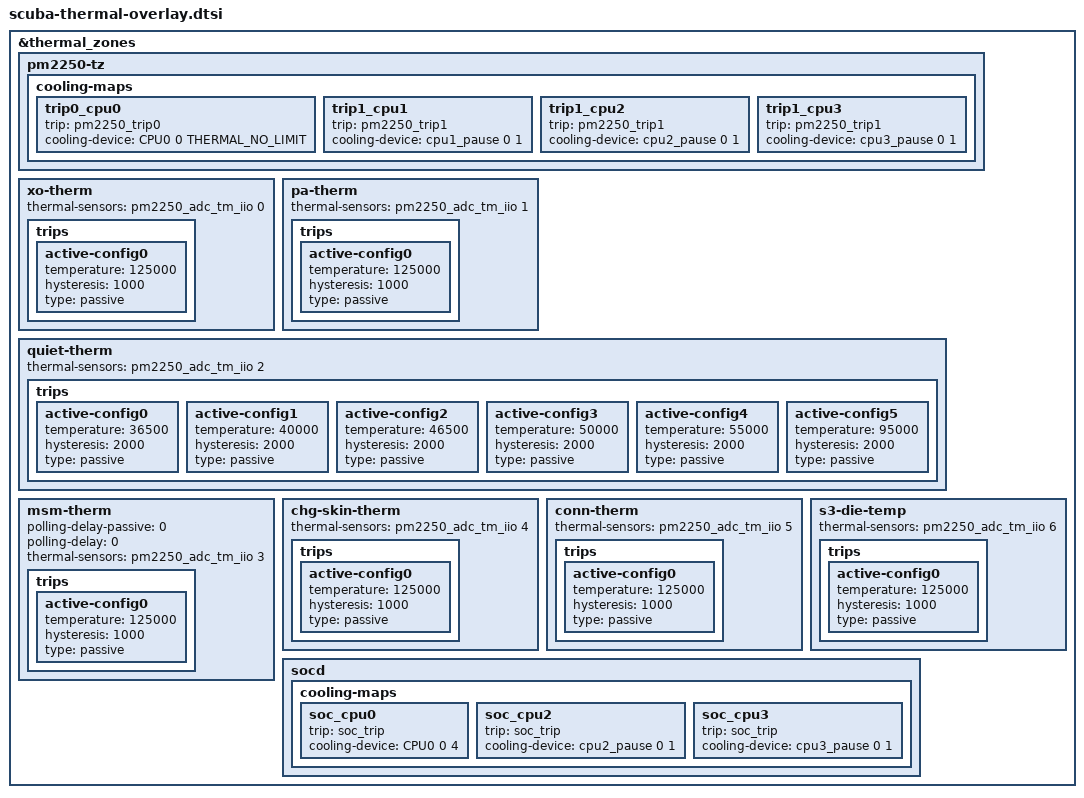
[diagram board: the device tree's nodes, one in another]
// SPDX-License-Identifier: BSD-3-Clause
/*
 * Copyright (c) Qualcomm Technologies, Inc. and/or its subsidiaries.
 */

#include <dt-bindings/thermal/thermal.h>

&thermal_zones {
	pm2250-tz {
		cooling-maps {
			trip0_cpu0 {
				trip = <&pm2250_trip0>;
				cooling-device =
					<&CPU0 0 THERMAL_NO_LIMIT>;
			};

			trip1_cpu1 {
				trip = <&pm2250_trip1>;
				cooling-device = <&cpu1_pause 0 1>;
			};

			trip1_cpu2 {
				trip = <&pm2250_trip1>;
				cooling-device = <&cpu2_pause 0 1>;
			};

			trip1_cpu3 {
				trip = <&pm2250_trip1>;
				cooling-device = <&cpu3_pause 0 1>;
			};
		};
	};

	xo-therm {
		thermal-sensors = <&pm2250_adc_tm_iio 0>;
		trips {
			active-config0 {
				temperature = <125000>;
				hysteresis = <1000>;
				type = "passive";
			};
		};
	};

	pa-therm {
		thermal-sensors = <&pm2250_adc_tm_iio 1>;
		trips {
			active-config0 {
				temperature = <125000>;
				hysteresis = <1000>;
				type = "passive";
			};
		};
	};

	quiet-therm {
		thermal-sensors = <&pm2250_adc_tm_iio 2>;
		trips {
			active-config0 {
				temperature = <36500>;
				hysteresis = <2000>;
				type = "passive";
			};

			active-config1 {
				temperature = <40000>;
				hysteresis = <2000>;
				type = "passive";
			};

			active-config2 {
				temperature = <46500>;
				hysteresis = <2000>;
				type = "passive";
			};

			active-config3 {
				temperature = <50000>;
				hysteresis = <2000>;
				type = "passive";
			};

			active-config4 {
				temperature = <55000>;
				hysteresis = <2000>;
				type = "passive";
			};

			active-config5 {
				temperature = <95000>;
				hysteresis = <2000>;
				type = "passive";
			};
		};
	};

	msm-therm {
		polling-delay-passive = <0>;
		polling-delay = <0>;
		thermal-sensors = <&pm2250_adc_tm_iio 3>;
		trips {
			active-config0 {
				temperature = <125000>;
				hysteresis = <1000>;
				type = "passive";
			};
		};
	};

	chg-skin-therm {
		thermal-sensors = <&pm2250_adc_tm_iio 4>;
		trips {
			active-config0 {
				temperature = <125000>;
				hysteresis = <1000>;
				type = "passive";
			};
		};
	};

	conn-therm {
		thermal-sensors = <&pm2250_adc_tm_iio 5>;
		trips {
			active-config0 {
				temperature = <125000>;
				hysteresis = <1000>;
				type = "passive";
			};
		};
	};

	s3-die-temp {
		thermal-sensors = <&pm2250_adc_tm_iio 6>;
		trips {
			active-config0 {
				temperature = <125000>;
				hysteresis = <1000>;
				type = "passive";
			};
		};
	};

	socd {
		cooling-maps {
			soc_cpu0 {
				trip = <&soc_trip>;
				cooling-device =
					<&CPU0 0 4>;
			};

			soc_cpu2 {
				trip = <&soc_trip>;
				cooling-device = <&cpu2_pause 0 1>;
			};

			soc_cpu3 {
				trip = <&soc_trip>;
				cooling-device = <&cpu3_pause 0 1>;
			};
		};
	};
};
